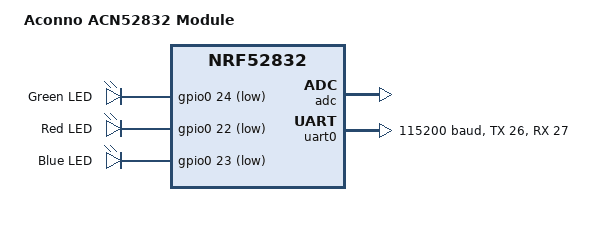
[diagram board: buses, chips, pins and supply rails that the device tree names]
/*
 * Copyright (c) 2017 Shawn Nock <shawn@monadnock.ca>
 * Copyright (c) 2017 Linaro Limited
 *
 * SPDX-License-Identifier: Apache-2.0
 */

/dts-v1/;
#include <nordic/nrf52832.dtsi>

/ {
	model = "Aconno ACN52832 Module";
	compatible = "nordic,acn52832", "nordic,nrf52832-qfaa",
		     "nordic,nrf52832";

	chosen {
		zephyr,console = &uart0;
#ifdef CONFIG_MCUMGR_SMP_UART
		zephyr,uart-mcumgr = &uart0;
#endif
		zephyr,sram = &sram0;
		zephyr,flash = &flash0;
	};

	leds {
		compatible = "gpio-leds";
		led0: led@0 {
			gpios = <&gpio0 24 GPIO_INT_ACTIVE_LOW>;
			label = "Green LED";
		};
		led1: led@1 {
			gpios = <&gpio0 22 GPIO_INT_ACTIVE_LOW>;
			label = "Red LED";
		};
		led2: led@2 {
			gpios = <&gpio0 23 GPIO_INT_ACTIVE_LOW>;
			label = "Blue LED";
		};
	};


	/* These aliases are provided for compatibility with samples */
	aliases {
		led0 = &led0;
		led1 = &led1;
		led2 = &led2;
	};
};

&adc {
	status ="ok";
};

&gpiote {
	status ="ok";
};

&gpio0 {
	status ="ok";
};

&uart0 {
	status = "ok";
	compatible = "nordic,nrf-uart";
	current-speed = <115200>;
	tx-pin = <26>;
	rx-pin = <27>;
	rts-pin = <25>;
	cts-pin = <28>;
};

/*
*&i2c0 {
*	status = "ok";
*	sda-pin = <26>;
*	scl-pin = <27>;
*};
*
*&i2c1 {
*	status = "ok";
*	sda-pin = <30>;
*	scl-pin = <31>;
*};
*/
&flash0 {
	/*
	 * For more information, see:
	 * http://docs.zephyrproject.org/devices/dts/flash_partitions.html
	 */
	partitions {
		compatible = "fixed-partitions";
		#address-cells = <1>;
		#size-cells = <1>;

		boot_partition: partition@0 {
			label = "mcuboot";
			reg = <0x00000000 0xc000>;
		};
		slot0_partition: partition@c000 {
			label = "image-0";
			reg = <0x0000C000 0x32000>;
		};
		slot1_partition: partition@3e000 {
			label = "image-1";
			reg = <0x0003E000 0x32000>;
		};
		scratch_partition: partition@70000 {
			label = "image-scratch";
			reg = <0x00070000 0xa000>;
		};

#if defined(CONFIG_FS_FLASH_STORAGE_PARTITION)
		storage_partition: partition@7a000 {
			label = "storage";
			reg = <0x0007a000 0x00006000>;
		};
#endif
	};
};
